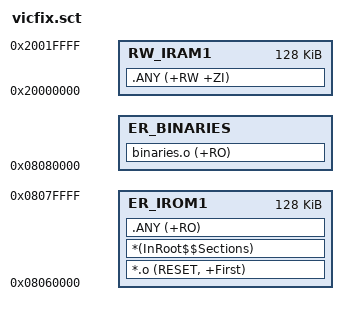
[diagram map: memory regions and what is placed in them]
; *************************************************************
; *** Scatter-Loading Description File generated by uVision ***
; *************************************************************

LR_IROM1 0x08060000 0x000A0000  {    ; load region size_region
  ; 64KB for program leaves the rest for resources
  ; If you run out, this can be expanded to 128KB MAX (due to fixture bootloader)
  ER_IROM1 0x08060000 0x00020000  {  ; load address = execution address
   *.o (RESET, +First)
   *(InRoot$$Sections)
   .ANY (+RO)
  }
  
  RW_IRAM1 0x20000000 0x00020000  {  ; RW data
   .ANY (+RW +ZI)
  }
  
  ;No-Init RAM must also be no-init by bootloader!
  ;RW_IRAM2 0x2001FFF0 UNINIT 0x00000010  {
  ; *(NoInit)  ;.ANY (+RW +ZI)
  ;}
  
  ; Put all the resources at the end of flash
  ; If you get a weird linker error on this section, add "--datacompressor off" to the Linker options
  ; It turns out Keil's linker can't compute the length of its own compressed sections!
  ER_BINARIES 0x08080000 ALIGN 0x20000 {
    binaries.o (+RO)
  }
}
